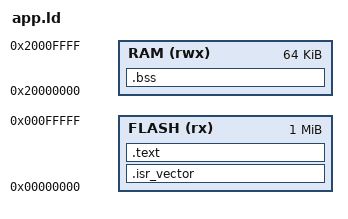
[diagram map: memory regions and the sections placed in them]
MEMORY
{
    FLASH (rx)  : ORIGIN = 0x00000000, LENGTH = 1024K
    RAM   (rwx) : ORIGIN = 0x20000000, LENGTH = 64K
}
ENTRY(Reset_Handler)
_estack = ORIGIN(RAM) + LENGTH(RAM);
SECTIONS
{
    .isr_vector : { KEEP(*(.isr_vector)) } > FLASH
    .text : { *(.text*) *(.rodata*) } > FLASH
    .bss (NOLOAD) : { *(.bss*) *(COMMON) } > RAM
    /DISCARD/ : { *(.ARM.exidx*) *(.ARM.extab*) *(.data*) }
}
